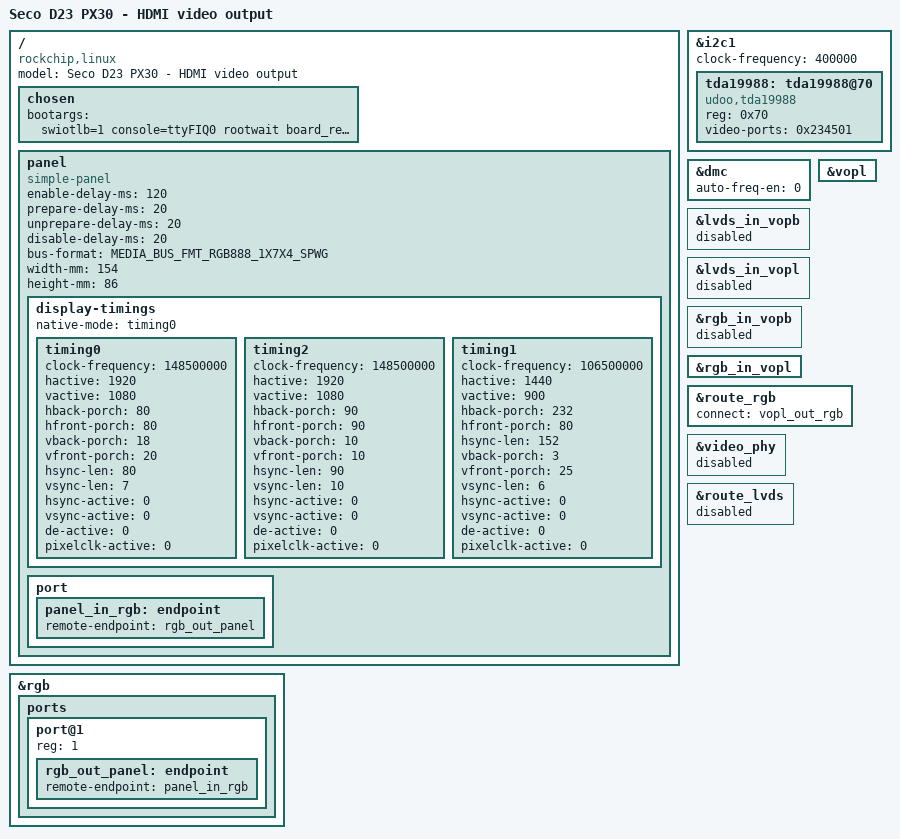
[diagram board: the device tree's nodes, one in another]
// SPDX-License-Identifier: (GPL-2.0+ OR MIT)
/*
 * Copyright (c) 2018 Fuzhou Rockchip Electronics Co., Ltd
 */

/dts-v1/;
#include "seco-px30-d23-revc.dtsi"

/ {
	model = "Seco D23 PX30 - HDMI video output";
	compatible = "rockchip,linux", "rockchip,rk3326";

	chosen {
		bootargs = "swiotlb=1 console=ttyFIQ0 rootwait board_revC-HDMI";
	};

	panel {
		compatible = "simple-panel";
		enable-delay-ms = <120>;
		prepare-delay-ms = <20>;
		unprepare-delay-ms = <20>;
		disable-delay-ms = <20>;
		bus-format = <MEDIA_BUS_FMT_RGB888_1X7X4_SPWG>;

		width-mm = <154>;
		height-mm = <86>;

		display-timings {
			native-mode = <&timing0>;

			timing0: timing0 {
				clock-frequency = <148500000>;
				hactive = <1920>;
				vactive = <1080>;
				hback-porch = <80>;
				hfront-porch = <80>;
				vback-porch = <18>;
				vfront-porch = <20>;
				hsync-len = <80>;
				vsync-len = <7>;
				hsync-active = <0>;
				vsync-active = <0>;
				de-active = <0>;
				pixelclk-active = <0>;
			};

			timing2: timing2 {
				clock-frequency = <148500000>;
				hactive = <1920>;
				vactive = <1080>;
				hback-porch = <90>;
				hfront-porch = <90>;
				vback-porch = <10>;
				vfront-porch = <10>;
				hsync-len = <90>;
				vsync-len = <10>;
				hsync-active = <0>;
				vsync-active = <0>;
				de-active = <0>;
				pixelclk-active = <0>;
			};

			timing1: timing1 {
				clock-frequency = <106500000>;
				hactive = <1440>;
				vactive = <900>;
				hback-porch = <232>;
				hfront-porch = <80>;
				hsync-len = <152>;
				vback-porch = <3>;
				vfront-porch = <25>;
				vsync-len = <6>;
				hsync-active = <0>;
				vsync-active = <0>;
				de-active = <0>;
				pixelclk-active = <0>;
			};

		};

		port {
			panel_in_rgb: endpoint {
				remote-endpoint = <&rgb_out_panel>;
			};
		};
	};
};

&rgb {
	status = "okay";
	ports {
		port@1 {
			reg = <1>;

			rgb_out_panel: endpoint {
				remote-endpoint = <&panel_in_rgb>;
			};
		};
	};
};

&i2c1 {
	status = "okay";
	clock-frequency = <400000>;

	tda19988: tda19988@70 {
		compatible = "udoo,tda19988";
		reg = <0x70>;
        	video-ports = <0x234501>;
		status = "okay";
	};
};

&dmc {
	auto-freq-en = <0>;
};

&lvds_in_vopb {
	status = "disabled";
};

&lvds_in_vopl {
	status = "disabled";
};

&rgb_in_vopb {
	status = "disabled";
};

&rgb_in_vopl {
	status = "okay";
};

&vopl {
	status = "okay";
};

&route_rgb {
	connect = <&vopl_out_rgb>;
	status = "okay";
};

&video_phy {
	status = "disabled";
};

&route_lvds {
	status = "disabled";
};
